# PY32F040xx register map
Vendor: Puya; Series: PY32F0; File version: 1.0.0
Arm 32-bit Cortex-M0+ Microcontroller based device, CPU clock up to 48 MHz.
CPU: CM0+ r0p1, little endian, no MPU, no FPU, 4 interrupt priority bits
Registers are 32-bit, read-write, reset 0x0 unless marked. A register's access mark holds for its fields unless they carry their own. Offsets are from the block's base; lines under a group give offsets from that group; [hi:lo] are bit positions; {n}, {i} and the like mark numbered series; 'fields as' and 'values as' point back to an identical list; <NAME> marks a mode.

## Memory map
0x40000000 TIM2 size 0x400 — desc TIM
0x40000400 TIM3 size 0x400 — General purpose timer
0x40001000 TIM6 size 0x400 — desc TIM
0x40001400 TIM7 size 0x400 — desc TIM
0x40002000 TIM14 size 0x400 — General purpose timer
0x40002400 LCD size 0x400 — LCD CONTROLLER
0x40002800 RTC size 0x400
0x40002C00 WWDG size 0x400 — Window watchdog
0x40003000 IWDG size 0x400 — Independent watchdog
0x40003800 SPI2 size 0x400
0x40004400 USART2 size 0x400
0x40004800 USART3 size 0x400 — desc USART
0x40004C00 USART4 size 0x400 — desc USART
0x40005400 I2C1 size 0x400 — Inter integrated circuit
0x40005800 I2C2 size 0x400 — desc I2C
0x40006C00 CTC size 0x400
0x40007000 PWR size 0x400 — Power control
0x40007C00 LPTIM1 size 0x400 — Low power timer
0x40010000 SYSCFG size 0x200
0x40010200 COMP1 size 0x10 — Comparator 1
0x40010210 COMP2 size 0x10 — Comparator2
0x40010300 OPA size 0x400 — des OPA
0x40012400 ADC size 0x400 — Analog to Digital Converter
0x40012C00 TIM1 size 0x400 — Advanced timer
0x40013000 SPI1 size 0x400 — Serial peripheral interface
0x40013800 USART1 size 0x400 — Universal synchronous asynchronous receiver transmitter
0x40014000 TIM15 size 0x400
0x40014400 TIM16 size 0x400 — General purpose timer
0x40014800 TIM17 size 0x400
0x40015800 DBG size 0x400 — Debug support
0x40020000 DMA size 0x400 — Direct memory access
0x40021000 RCC size 0x400 — Reset and clock control
0x40021800 EXTI size 0x400 — External interrupt/event controller
0x40022000 FLASH size 0x400
0x40023000 CRC size 0x400 — CRC calculation unit
0x40023800 DIV size 0x400 — Hardware Divider
0x50000000 GPIOA size 0x400 — General-purpose I/Os
0x50000400 GPIOB size 0x400 — General-purpose I/Os
0x50000800 GPIOC size 0x400 — General-purpose I/Os
0x50001400 GPIOF size 0x400 — General-purpose I/Os

## Interrupts
0 WWDG — Window WatchDog Interrupt
1 PVD (EXTI) — PVD Interrupt through EXTI Lines 16
2 RTC — RTC Interrupt through EXTI Lines 19
3 FLASH — FLASH global Interrupt
4 RCC_CTC (CTC, RCC) — RCC and CTC global Interrupts
5 EXTI0_1 (EXTI) — EXTI Line 0 and 1 Interrupt
6 EXTI2_3 (EXTI) — EXTI Line 2 and 3 Interrupt
7 EXTI4_15 (EXTI) — EXTI Line 4 to 15 Interrupt
8 LCD — LCD global Interrupt
9 DMA1_Channel1 (DMA) — DMA1 Channel 1 Interrupt
10 DMA1_Channel2_3 (DMA) — DMA1 Channel 2 and Channel 3 Interrupt
11 DMA1_Channel4_5_6_7 (DMA) — DMA1 Channel 4, 5, 6, 7 Interrupts
12 ADC_COMP (ADC, COMP1, COMP2) — ADC and COMP Interrupt through EXTI Lines 17 and 18
13 TIM1_BRK_UP_TRG_COM (TIM1) — TIM1 Break, Update, Trigger and Commutation Interrupt
14 TIM1_CC (TIM1) — TIM1 Capture Compare Interrupt
15 TIM2 — TIM2 global Interrupt
16 TIM3 — TIM3 global Interrupt
17 TIM6_LPTIM1 (LPTIM1, TIM6) — TIM6, LPTIM1 global Interrupts
18 TIM7 — TIM7 global Interrupt
19 TIM14 — TIM14 global Interrupt
20 TIM15 — TIM15 global Interrupt
21 TIM16 — TIM16 global Interrupt
22 TIM17 — TIM17 global Interrupt
23 I2C1 — I2C1 global Interrupt
24 I2C2 — I2C2 Event Interrupt
25 SPI1 — SPI1 global Interrupt
26 SPI2 — SPI2 global Interrupt
27 USART1 — USART1 global Interrupt
28 USART2 — USART2 global Interrupt
29 USART3_4 (USART3, USART4) — USART3, 4 global Interrupts

## COMP1 — Comparator 1
Base 0x40010200
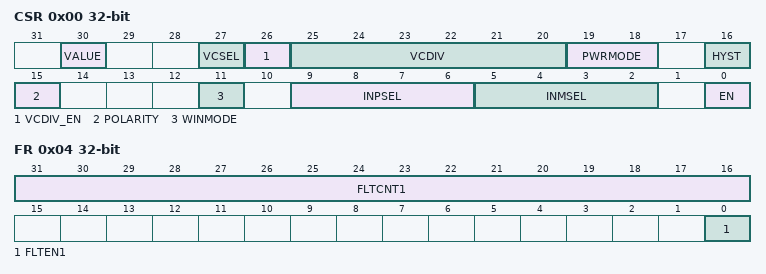
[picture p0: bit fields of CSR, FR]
0x00 CSR — COMP control and status register
  [30] VALUE — Comparator output status
    on read: 0=Low (Comparator output is low); 1=High (Comparator output is high)
  [27] VCSEL
    0=Vcc; 1=ADC reference voltage
  [26] VCDIV_EN
    0=Disabled (Voltage division not enabled); 1=Enabled (Voltage division enabled)
  [25:20] VCDIV
  [19:18] PWRMODE — Comparator power mode selector
    0=High speed 250 ua; 1=Medium speed 5 ua
  [16] HYST — Comparator hysteresis enable selector
    0=No (no Comp1 hysteresis); 1=Yes (Comp1 hysteresis voltage approx 20mV)
  [15] POLARITY — Comparator polarity selector
    0=NotInverted (Output is not inverted); 1=Inverted (Output is inverted)
  [11] WINMODE — Comparator non-inverting input selector for window mode
    0=Disabled; 1=Enabled
  [9:6] INPSEL — Comparator signal selector for non-inverting input
    {v}=Inp{v} (COMP1_INP{v} from PC{v}) (v=0..3); {v}=Inp{v} (COMP1_INP{v} from PA{v-4}) (v=4..11); 12=Inp12 (COMP1_INP12 from PB4); 13=Inp13 (COMP1_INP13 from PB5); 14=Inp14 (COMP1_INP14 from PB6)
  [5:2] INMSEL — Comparator signal selector for inverting input INM
    {v}=Inm{v} (COMP1_INM{v} from PA{v}) (v=0..7); 8=Inm8 (COMP1_INM8 from PC4); 9=Inm9 (COMP1_INM9 from PC5); 10=Inm11 (COMP1_INM11 from resistor voltage divider); 11=Inm12 (COMP1_INM12 from TS_VIN); 12=Inm13 (COMP1_INM13 from VREF1P2); 13=Inm14 (COMP1_INM14 from VREFBUF); 14=Inm15 (COMP1_INM15 from OPA1_VIN)
  [0] EN — COMP enable bit
    0=Disabled (Comparator 1 disabled); 1=Enabled (Comparator 1 enabled)
0x04 FR — Comparator Filter register
  [31:16] FLTCNT1 — Comparator filter and counter
  [0] FLTEN1 — Filter enable bit
    0=Disabled (Comparator digital filter disabled); 1=Enabled (Comparator digital filter enabled)
